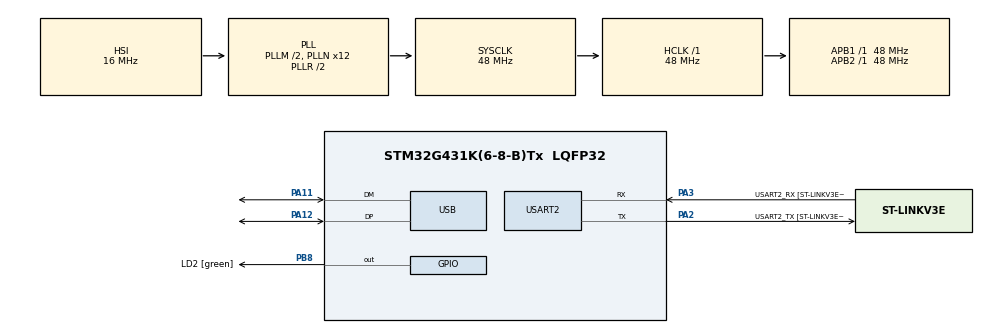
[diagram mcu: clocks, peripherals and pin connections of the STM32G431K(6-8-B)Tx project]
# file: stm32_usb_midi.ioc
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Mcu.Family=STM32G4
Mcu.Name=STM32G431K(6-8-B)Tx
Mcu.Package=LQFP32
NVIC.PriorityGroup=NVIC_PRIORITYGROUP_4
NVIC.USB_LP_IRQn=true\:0\:0\:false\:false\:true\:false\:true
PA11.Mode=Device
PA11.Signal=USB_DM
PA12.Mode=Device
PA12.Signal=USB_DP
PA13.GPIO_Label=T_SWDIO
PA13.Mode=Serial_Wire
PA13.Signal=SYS_JTMS-SWDIO
PA14.GPIO_Label=T_SWCLK
PA14.Mode=Serial_Wire
PA14.Signal=SYS_JTCK-SWCLK
PA2.GPIO_Label=USART2_TX [ST-LINKV3E_VCP_RX]
PA2.Mode=Asynchronous
PA2.Signal=USART2_TX
PA3.GPIO_Label=USART2_RX [ST-LINKV3E_VCP_TX]
PA3.Mode=Asynchronous
PA3.Signal=USART2_RX
PB3.GPIO_Label=T_SWO
PB3.Signal=SYS_JTDO-SWO
PB8-BOOT0.GPIO_Label=LD2 [green]
PB8-BOOT0.Signal=GPIO_Output
ProjectManager.HeapSize=0x200
ProjectManager.StackSize=0x400
ProjectManager.TargetToolchain=STM32CubeIDE
RCC.ADC12Freq_Value=48000000
RCC.AHBFreq_Value=48000000
RCC.APB1Freq_Value=48000000
RCC.APB1TimFreq_Value=48000000
RCC.APB2Freq_Value=48000000
RCC.APB2TimFreq_Value=48000000
RCC.CortexFreq_Value=48000000
RCC.EXTERNAL_CLOCK_VALUE=12288000
RCC.HCLKFreq_Value=48000000
RCC.HSE_VALUE=8000000
RCC.HSI48_VALUE=48000000
RCC.HSI_VALUE=16000000
RCC.LSE_VALUE=32768
RCC.PLLM=RCC_PLLM_DIV2
RCC.PLLN=12
RCC.SYSCLKFreq_VALUE=48000000
RCC.SYSCLKSource=RCC_SYSCLKSOURCE_PLLCLK
RCC.USBFreq_Value=48000000
RCC.VCOOutputFreq_Value=96000000
USART2.VirtualMode-Asynchronous=VM_ASYNC
USART2.WordLength=WORDLENGTH_8B
USB_DEVICE.CLASS_NAME_FS=CDC
USB_DEVICE.VirtualMode=Cdc
USB_DEVICE.VirtualModeFS=Cdc_FS
VP_SYS_VS_DBSignals.Mode=DisableDeadBatterySignals
VP_USB_DEVICE_VS_USB_DEVICE_CDC_FS.Mode=CDC_FS
board=NUCLEO-G431KB

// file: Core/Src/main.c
/* USER CODE BEGIN Header */
/**
  ******************************************************************************
  * @file           : main.c
  * @brief          : Main program body
  ******************************************************************************
  * @attention
  *
  * <h2><center>&copy; Copyright (c) 2020 STMicroelectronics.
  * All rights reserved.</center></h2>
  *
  * This software component is licensed by ST under BSD 3-Clause license,
  * the "License"; You may not use this file except in compliance with the
  * License. You may obtain a copy of the License at:
  *                        opensource.org/licenses/BSD-3-Clause
  *
  ******************************************************************************
  */
/* USER CODE END Header */

#include "main.h"
#include "usb_device.h"

/* USER CODE BEGIN Includes */
#include <usbd_midi_if.h>

/* USER CODE END Includes */

/* USER CODE BEGIN PTD */
/*
 *
 amidi -S 'F0 43 10 4C 00 00 7E 00 F7' -p hw:2,0,0
 amidi -p hw:2,0,0 -s file
*/
/* USER CODE END PTD */

UART_HandleTypeDef huart2;

/* USER CODE BEGIN PV */
uint8_t		midi_buffer[64], midi_flag = 0;
uint16_t	midi_len=0;

/* USER CODE END PV */

void SystemClock_Config(void);
static void MX_GPIO_Init(void);
static void MX_USART2_UART_Init(void);

int main(void)
{

  /* MCU Configuration--------------------------------------------------------*/

  /* Reset of all peripherals, Initializes the Flash interface and the Systick. */
  HAL_Init();

  /* Configure the system clock */
  SystemClock_Config();

  /* Initialize all configured peripherals */
  MX_GPIO_Init();
  MX_USART2_UART_Init();
  MX_USB_Device_Init(0); /* 0 is midi, 1 is CDC */
  /* USER CODE BEGIN 2 */
  MIDI_SetRxPointer_FS((uint32_t )&midi_buffer[0],(uint32_t )&midi_len,(uint32_t )&midi_flag);
  /* USER CODE END 2 */

  /* Infinite loop */
  /* USER CODE BEGIN WHILE */
  while (1)
  {
	  if ( midi_flag == 1)
	  {
		  midi_flag = 0;
	  }
    /* USER CODE END WHILE */

  }
}

void SystemClock_Config(void)
{
  RCC_OscInitTypeDef RCC_OscInitStruct = {0};
  RCC_ClkInitTypeDef RCC_ClkInitStruct = {0};
  RCC_PeriphCLKInitTypeDef PeriphClkInit = {0};

  /** Configure the main internal regulator output voltage
  */
  HAL_PWREx_ControlVoltageScaling(PWR_REGULATOR_VOLTAGE_SCALE1);
  /** Initializes the CPU, AHB and APB busses clocks
  */
  RCC_OscInitStruct.OscillatorType = RCC_OSCILLATORTYPE_HSI;
  RCC_OscInitStruct.HSIState = RCC_HSI_ON;
  RCC_OscInitStruct.HSICalibrationValue = RCC_HSICALIBRATION_DEFAULT;
  RCC_OscInitStruct.PLL.PLLState = RCC_PLL_ON;
  RCC_OscInitStruct.PLL.PLLSource = RCC_PLLSOURCE_HSI;
  RCC_OscInitStruct.PLL.PLLM = RCC_PLLM_DIV2;
  RCC_OscInitStruct.PLL.PLLN = 12;
  RCC_OscInitStruct.PLL.PLLP = RCC_PLLP_DIV2;
  RCC_OscInitStruct.PLL.PLLQ = RCC_PLLQ_DIV2;
  RCC_OscInitStruct.PLL.PLLR = RCC_PLLR_DIV2;
  if (HAL_RCC_OscConfig(&RCC_OscInitStruct) != HAL_OK)
  {
    Error_Handler();
  }
  /** Initializes the CPU, AHB and APB busses clocks
  */
  RCC_ClkInitStruct.ClockType = RCC_CLOCKTYPE_HCLK|RCC_CLOCKTYPE_SYSCLK
                              |RCC_CLOCKTYPE_PCLK1|RCC_CLOCKTYPE_PCLK2;
  RCC_ClkInitStruct.SYSCLKSource = RCC_SYSCLKSOURCE_PLLCLK;
  RCC_ClkInitStruct.AHBCLKDivider = RCC_SYSCLK_DIV1;
  RCC_ClkInitStruct.APB1CLKDivider = RCC_HCLK_DIV1;
  RCC_ClkInitStruct.APB2CLKDivider = RCC_HCLK_DIV1;

  if (HAL_RCC_ClockConfig(&RCC_ClkInitStruct, FLASH_LATENCY_2) != HAL_OK)
  {
    Error_Handler();
  }
  /** Initializes the peripherals clocks
  */
  PeriphClkInit.PeriphClockSelection = RCC_PERIPHCLK_USART2|RCC_PERIPHCLK_USB;
  PeriphClkInit.Usart2ClockSelection = RCC_USART2CLKSOURCE_PCLK1;
  PeriphClkInit.UsbClockSelection = RCC_USBCLKSOURCE_PLL;
  if (HAL_RCCEx_PeriphCLKConfig(&PeriphClkInit) != HAL_OK)
  {
    Error_Handler();
  }
}

static void MX_USART2_UART_Init(void)
{

  huart2.Instance = USART2;
  huart2.Init.BaudRate = 115200;
  huart2.Init.WordLength = UART_WORDLENGTH_8B;
  huart2.Init.StopBits = UART_STOPBITS_1;
  huart2.Init.Parity = UART_PARITY_NONE;
  huart2.Init.Mode = UART_MODE_TX_RX;
  huart2.Init.HwFlowCtl = UART_HWCONTROL_NONE;
  huart2.Init.OverSampling = UART_OVERSAMPLING_16;
  huart2.Init.OneBitSampling = UART_ONE_BIT_SAMPLE_DISABLE;
  huart2.Init.ClockPrescaler = UART_PRESCALER_DIV1;
  huart2.AdvancedInit.AdvFeatureInit = UART_ADVFEATURE_NO_INIT;
  if (HAL_UART_Init(&huart2) != HAL_OK)
  {
    Error_Handler();
  }
  if (HAL_UARTEx_SetTxFifoThreshold(&huart2, UART_TXFIFO_THRESHOLD_1_8) != HAL_OK)
  {
    Error_Handler();
  }
  if (HAL_UARTEx_SetRxFifoThreshold(&huart2, UART_RXFIFO_THRESHOLD_1_8) != HAL_OK)
  {
    Error_Handler();
  }
  if (HAL_UARTEx_DisableFifoMode(&huart2) != HAL_OK)
  {
    Error_Handler();
  }

}

static void MX_GPIO_Init(void)
{
  GPIO_InitTypeDef GPIO_InitStruct = {0};

  /* GPIO Ports Clock Enable */
  __HAL_RCC_GPIOA_CLK_ENABLE();
  __HAL_RCC_GPIOB_CLK_ENABLE();

  /*Configure GPIO pin Output Level */
  HAL_GPIO_WritePin(LD2_GPIO_Port, LD2_Pin, GPIO_PIN_RESET);

  /*Configure GPIO pin : LD2_Pin */
  GPIO_InitStruct.Pin = LD2_Pin;
  GPIO_InitStruct.Mode = GPIO_MODE_OUTPUT_PP;
  GPIO_InitStruct.Pull = GPIO_NOPULL;
  GPIO_InitStruct.Speed = GPIO_SPEED_FREQ_LOW;
  HAL_GPIO_Init(LD2_GPIO_Port, &GPIO_InitStruct);

}

void Error_Handler(void)
{
}

/************************ (C) COPYRIGHT STMicroelectronics *****END OF FILE****/
